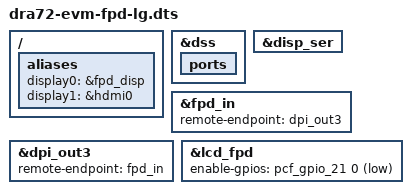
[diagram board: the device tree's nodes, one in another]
#include "dra72-evm.dts"
#include "dra7x-evm-fpd-lg.dtsi"

/* Set display aliases for use by Android */
/ {
	aliases {
		display0 = &fpd_disp;
		display1 = &hdmi0;
	};
};

&dss {
	ports {
		status = "ok";
	};
};

&disp_ser {
	status = "ok";
	ranges = <0x2c 0x2c>,
		<0x1c 0x1c>;
};

/* Tie the end points of DSS and FPDLink together */

&fpd_in {
	remote-endpoint = <&dpi_out3>;
};

&dpi_out3 {
	remote-endpoint = <&fpd_in>;
};

&lcd_fpd {
	enable-gpios = <&pcf_gpio_21 0 GPIO_ACTIVE_LOW>;
	/* P0, SEL_GPMC_AD_VID_S0 */

	status = "ok";
};
